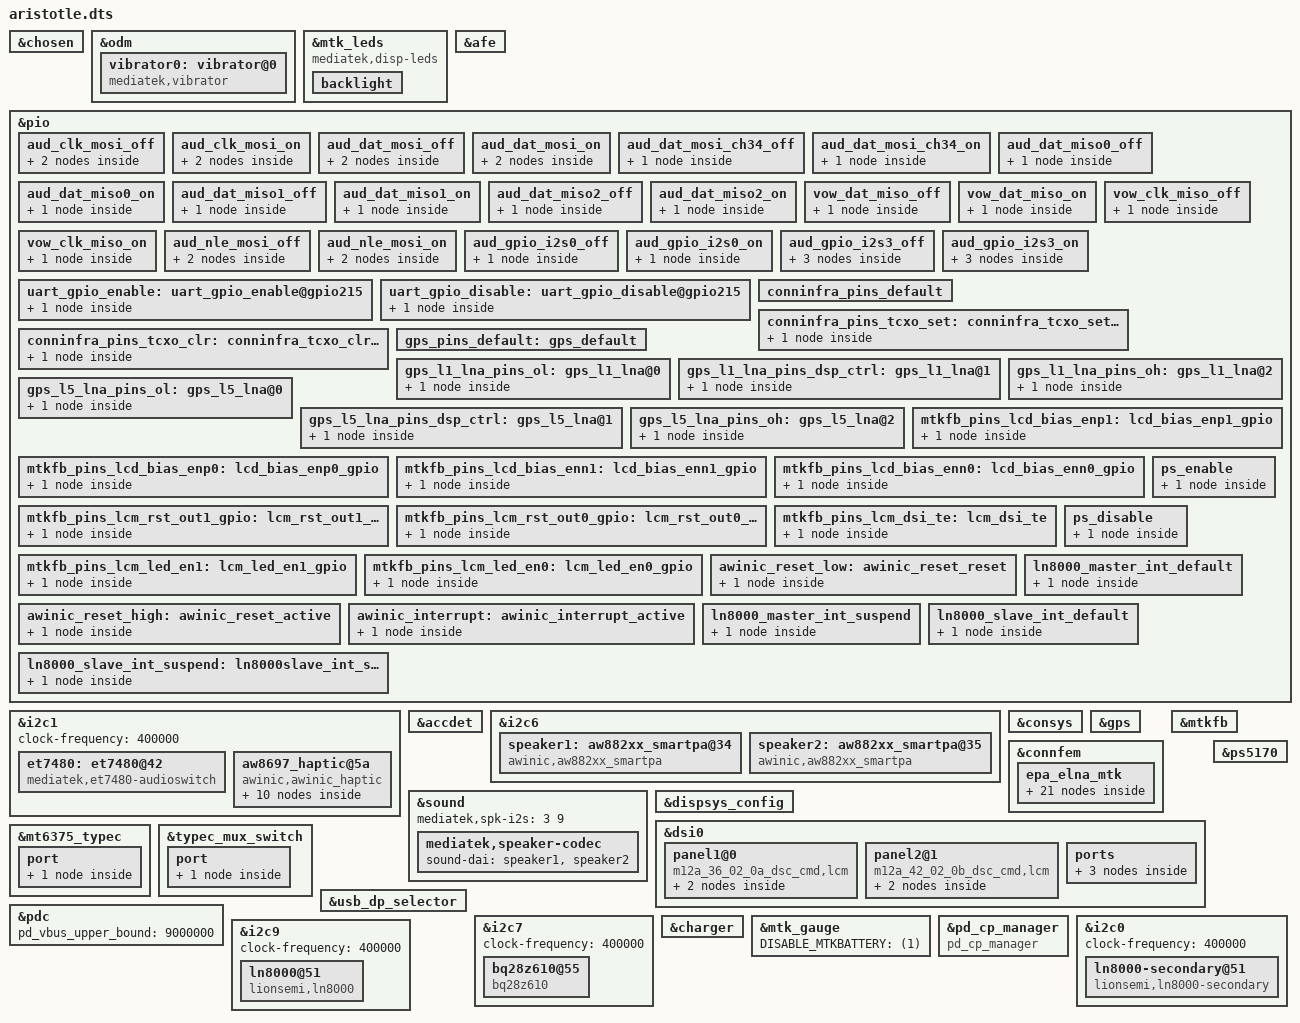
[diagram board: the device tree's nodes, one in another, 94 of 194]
// SPDX-License-Identifier: (GPL-2.0 OR MIT)
/*
 * Copyright (C) 2020 MediaTek Inc.
 * Author: Chun-Hung Wu <chun-hung.wu@mediatek.com>
 */
/dts-v1/;
/plugin/;
#include <dt-bindings/interrupt-controller/arm-gic.h>
#include <dt-bindings/interrupt-controller/irq.h>
#include <dt-bindings/phy/phy.h>
#include <dt-bindings/pinctrl/mt6895-pinfunc.h>
#include "mediatek/aristotle-mt6895-common.dtsi"

&chosen {
	bootargs_ext = "console=tty0 root=/dev/ram \
androidboot.hardware=mt6895";
};

&odm {
	vibrator0:vibrator@0 {
		compatible = "mediatek,vibrator";
		vib_timer = <25>;
		vib_limit = <9>;
		vib_vol= <9>;
	};
};

&mtk_leds {
	compatible = "mediatek,disp-leds";

	backlight {
		max-brightness = <16383>;
		min-brightness = <1>;
		max-hw-brightness = <16383>;
		led-mode = <4>;
		default-state = "FifteenPercent";
	};
};

/* AUDIO GPIO standardization start */
&afe {
	pinctrl-names = "aud_clk_mosi_off",
			"aud_clk_mosi_on",
			"aud_dat_mosi_off",
			"aud_dat_mosi_on",
			"aud_dat_mosi_ch34_off",
			"aud_dat_mosi_ch34_on",
			"aud_dat_miso0_off",
			"aud_dat_miso0_on",
			"aud_dat_miso1_off",
			"aud_dat_miso1_on",
			"aud_dat_miso2_off",
			"aud_dat_miso2_on",
			"vow_dat_miso_off",
			"vow_dat_miso_on",
			"vow_clk_miso_off",
			"vow_clk_miso_on",
			"aud_gpio_i2s3_off",
			"aud_gpio_i2s3_on",
			"aud_gpio_i2s0_off",
			"aud_gpio_i2s0_on";
	pinctrl-0 = <&aud_clk_mosi_off>;
	pinctrl-1 = <&aud_clk_mosi_on>;
	pinctrl-2 = <&aud_dat_mosi_off>;
	pinctrl-3 = <&aud_dat_mosi_on>;
	pinctrl-4 = <&aud_dat_mosi_ch34_off>;
	pinctrl-5 = <&aud_dat_mosi_ch34_on>;
	pinctrl-6 = <&aud_dat_miso0_off>;
	pinctrl-7 = <&aud_dat_miso0_on>;
	pinctrl-8 = <&aud_dat_miso1_off>;
	pinctrl-9 = <&aud_dat_miso1_on>;
	pinctrl-10 = <&aud_dat_miso2_off>;
	pinctrl-11 = <&aud_dat_miso2_on>;
	pinctrl-12 = <&vow_dat_miso_off>;
	pinctrl-13 = <&vow_dat_miso_on>;
	pinctrl-14 = <&vow_clk_miso_off>;
	pinctrl-15 = <&vow_clk_miso_on>;
	pinctrl-16 = <&aud_gpio_i2s3_off>;
	pinctrl-17 = <&aud_gpio_i2s3_on>;
	pinctrl-18 = <&aud_gpio_i2s0_off>;
	pinctrl-19 = <&aud_gpio_i2s0_on>;
};
&pio {
	aud_clk_mosi_off: aud_clk_mosi_off {
		pins_cmd1_dat {
			pinmux = <PINMUX_GPIO202__FUNC_GPIO202>;
			input-enable;
			bias-pull-down;
		};
		pins_cmd2_dat {
			pinmux = <PINMUX_GPIO203__FUNC_GPIO203>;
			input-enable;
			bias-pull-down;
		};
	};
	aud_clk_mosi_on: aud_clk_mosi_on {
		pins_cmd1_dat {
			pinmux = <PINMUX_GPIO202__FUNC_AUD_CLK_MOSI>;
			input-schmitt-enable;
			bias-disable;
		};
		pins_cmd2_dat {
			pinmux = <PINMUX_GPIO203__FUNC_AUD_SYNC_MOSI>;
			input-schmitt-enable;
			bias-disable;
		};
	};
	aud_dat_mosi_off: aud_dat_mosi_off {
		pins_cmd1_dat {
			pinmux = <PINMUX_GPIO204__FUNC_GPIO204>;
			input-enable;
			bias-pull-down;
		};
		pins_cmd2_dat {
			pinmux = <PINMUX_GPIO205__FUNC_GPIO205>;
			input-enable;
			bias-pull-down;
		};
	};
	aud_dat_mosi_on: aud_dat_mosi_on {
		pins_cmd1_dat {
			pinmux = <PINMUX_GPIO204__FUNC_AUD_DAT_MOSI0>;
			input-schmitt-enable;
			bias-disable;
		};
		pins_cmd2_dat {
			pinmux = <PINMUX_GPIO205__FUNC_AUD_DAT_MOSI1>;
			input-schmitt-enable;
			bias-disable;
		};
	};
	aud_dat_mosi_ch34_off: aud_dat_mosi_ch34_off {
		pins_cmd1_dat {
			pinmux = <PINMUX_GPIO206__FUNC_GPIO206>;
			input-enable;
			bias-pull-down;
		};
	};
	aud_dat_mosi_ch34_on: aud_dat_mosi_ch34_on {
		pins_cmd1_dat {
			pinmux = <PINMUX_GPIO206__FUNC_AUD_DAT_MOSI2>;
			input-schmitt-enable;
			bias-disable;
		};
	};
	aud_dat_miso0_off: aud_dat_miso0_off {
		pins_cmd1_dat {
			pinmux = <PINMUX_GPIO209__FUNC_GPIO209>;
			input-enable;
			bias-pull-down;
		};
	};
	aud_dat_miso0_on: aud_dat_miso0_on {
		pins_cmd1_dat {
			pinmux = <PINMUX_GPIO209__FUNC_AUD_DAT_MISO0>;
			input-schmitt-enable;
			bias-disable;
		};
	};
	aud_dat_miso1_off: aud_dat_miso1_off {
		pins_cmd1_dat {
			pinmux = <PINMUX_GPIO210__FUNC_GPIO210>;
			input-enable;
			bias-disable;
		};
	};
	aud_dat_miso1_on: aud_dat_miso1_on {
		pins_cmd1_dat {
			pinmux = <PINMUX_GPIO210__FUNC_AUD_DAT_MISO1>;
			input-schmitt-enable;
			bias-disable;
		};
	};
	aud_dat_miso2_off: aud_dat_miso2_off {
		pins_cmd1_dat {
			pinmux = <PINMUX_GPIO211__FUNC_GPIO211>;
			input-enable;
			bias-pull-down;
		};
	};
	aud_dat_miso2_on: aud_dat_miso2_on {
		pins_cmd1_dat {
			pinmux = <PINMUX_GPIO211__FUNC_AUD_DAT_MISO2>;
			input-schmitt-enable;
			bias-disable;
		};
	};
	vow_dat_miso_off: vow_dat_miso_off {
		pins_cmd1_dat {
			pinmux = <PINMUX_GPIO209__FUNC_GPIO209>;
			input-enable;
			bias-pull-down;
		};
	};
	vow_dat_miso_on: vow_dat_miso_on {
		pins_cmd1_dat {
			pinmux = <PINMUX_GPIO209__FUNC_VOW_DAT_MISO>;
			input-schmitt-enable;
			bias-disable;
		};
	};
	vow_clk_miso_off: vow_clk_miso_off {
		pins_cmd1_dat {
			pinmux = <PINMUX_GPIO210__FUNC_GPIO210>;
			input-enable;
			bias-pull-down;
		};
	};
	vow_clk_miso_on: vow_clk_miso_on {
		pins_cmd1_dat {
			pinmux = <PINMUX_GPIO210__FUNC_VOW_CLK_MISO>;
			input-schmitt-enable;
			bias-disable;
		};
	};
	aud_nle_mosi_off: aud_nle_mosi_off {
		pins_cmd1_dat {
			pinmux = <PINMUX_GPIO207__FUNC_GPIO207>;
			input-enable;
			bias-pull-down;
		};
		pins_cmd2_dat {
			pinmux = <PINMUX_GPIO208__FUNC_GPIO208>;
			input-enable;
			bias-pull-down;
		};
	};
	aud_nle_mosi_on: aud_nle_mosi_on {
		pins_cmd1_dat {
			pinmux = <PINMUX_GPIO207__FUNC_AUD_NLE_MOSI1>;
			input-schmitt-enable;
			bias-disable;
		};
		pins_cmd2_dat {
			pinmux = <PINMUX_GPIO208__FUNC_AUD_NLE_MOSI0>;
			input-schmitt-enable;
			bias-disable;
		};
	};
	aud_gpio_i2s0_off: aud_gpio_i2s0_off {
		pins_cmd1_dat {
			pinmux = <PINMUX_GPIO23__FUNC_GPIO23>;
			input-enable;
			bias-pull-down;
		};
	};
	aud_gpio_i2s0_on: aud_gpio_i2s0_on {
		pins_cmd1_dat {
			pinmux = <PINMUX_GPIO23__FUNC_I2S0_DI>;
			input-schmitt-enable;
			bias-disable;
		};
	};
	aud_gpio_i2s3_off: aud_gpio_i2s3_off {
		pins_cmd1_dat {
			pinmux = <PINMUX_GPIO21__FUNC_GPIO21>;
			input-enable;
			bias-pull-down;
		};
		pins_cmd2_dat {
			pinmux = <PINMUX_GPIO22__FUNC_GPIO22>;
			input-enable;
			bias-pull-down;
		};
		pins_cmd3_dat {
			pinmux = <PINMUX_GPIO24__FUNC_GPIO24>;
			input-enable;
			bias-pull-down;
		};
	};
	aud_gpio_i2s3_on: aud_gpio_i2s3_on {
		pins_cmd1_dat {
			pinmux = <PINMUX_GPIO21__FUNC_I2S3_BCK>;
			input-schmitt-enable;
			bias-disable;
		};
		pins_cmd2_dat {
			pinmux = <PINMUX_GPIO22__FUNC_I2S3_LRCK>;
			input-schmitt-enable;
			bias-disable;
		};
		pins_cmd3_dat {
			pinmux = <PINMUX_GPIO24__FUNC_I2S3_DO>;
			input-schmitt-enable;
			bias-disable;
		};
	};
};
/* AUDIO GPIO standardization end */

/* Audio Switch start */
&pio {
        uart_gpio_enable: uart_gpio_enable@gpio215 {
                pins_cmd_dat {
                        pinmux = <PINMUX_GPIO215__FUNC_GPIO215>;
                        slew-rate = <1>;
                        bias-disable;
                        output-low;
                };
        };
        uart_gpio_disable: uart_gpio_disable@gpio215 {
                pins_cmd_dat {
                        pinmux = <PINMUX_GPIO215__FUNC_GPIO215>;
                        slew-rate = <1>;
                        bias-disable;
                        output-high;
                };
        };
};
&i2c1 {
        et7480: et7480@42 {
                status = "ok";
                compatible = "mediatek,et7480-audioswitch";
                reg = <0x42>;
                pinctrl-names = "uart_enable", "uart_disable";
                pinctrl-0 = <&uart_gpio_enable>;
                pinctrl-1 = <&uart_gpio_disable>;
        };
};
&accdet {
        /* accdet micbias voltage: 0x09:2.85v 0x08:2.8v 0x07,
         * 2.7v;0x05,2.5v;0x02,1.9v
         */
        accdet-mic-vol = <5>;
        /*1:ACC mode, 2:low cost without in bias, 6:low cost with in bias*/
        accdet-mic-mode = <2>;
        et7480-i2c-handle = <&et7480>;
};
/* Audio Swtich end */

&i2c6 {
	speaker1: aw882xx_smartpa@34 {
		compatible = "awinic,aw882xx_smartpa";
		#sound-dai-cells = <0>;
		reg = <0x34>;
		reset-gpio = <&pio 213 0>;
		irq-gpio = <&pio 15 0x0>;
		spk-sw-gpio = <&pio 160 0x0>;
		sound-channel = <0>;
		aw-re-min = <4000>;
		aw-re-max= <30000>;
		/*aw-cali-mode = "none";*/
		status = "okay";
	};

        speaker2: aw882xx_smartpa@35 {
		compatible = "awinic,aw882xx_smartpa";
		#sound-dai-cells = <0>;
		reg = <0x35>;
		reset-gpio = <&pio 213 0>;
		irq-gpio = <&pio 19 0x0>;
		sound-channel = <1>;
		aw-re-min = <4000>;
		aw-re-max= <30000>;
		/*aw-cali-mode = "none";*/
		status = "okay";
        };
};

/* CONNSYS TCXO GPIO start */
&consys {
	tcxo_support = "false";
	pinctrl-names = "default", "conninfra_tcxo_set", "conninfra_tcxo_clr";
	pinctrl-0 = <&conninfra_pins_default>;
	pinctrl-1 = <&conninfra_pins_tcxo_set>;
	pinctrl-2 = <&conninfra_pins_tcxo_clr>;
	status = "okay";
};

&pio {
	conninfra_pins_default: conninfra_pins_default {
	};
	conninfra_pins_tcxo_set: conninfra_tcxo_set@gpio {
		pins_cmd_dat {
			pinmux = <PINMUX_GPIO108__FUNC_CONN_TCXOENA_REQ>;
		};
	};
	conninfra_pins_tcxo_clr: conninfra_tcxo_clr@gpio {
		pins_cmd_dat {
			pinmux = <PINMUX_GPIO108__FUNC_GPIO108>;
		};
	};
};
/* CONNSYS TCXO GPIO end */

/* GPS GPIO standardization start */
&pio {
	gps_pins_default: gps_default {
	};

	gps_l1_lna_pins_ol: gps_l1_lna@0 {
		pins_cmd_dat {
			pinmux = <PINMUX_GPIO16__FUNC_GPIO16>;
			output-low;
		};
	};
	gps_l1_lna_pins_dsp_ctrl: gps_l1_lna@1 {
		pins_cmd_dat {
			pinmux = <PINMUX_GPIO16__FUNC_GPS_L1_ELNA_EN>;
		};
	};
	gps_l1_lna_pins_oh: gps_l1_lna@2 {
		pins_cmd_dat {
			pinmux = <PINMUX_GPIO16__FUNC_GPIO16>;
			output-high;
		};
	};

	gps_l5_lna_pins_ol: gps_l5_lna@0 {
		pins_cmd_dat {
			pinmux = <PINMUX_GPIO17__FUNC_GPIO17>;
			output-low;
		};
	};
	gps_l5_lna_pins_dsp_ctrl: gps_l5_lna@1 {
		pins_cmd_dat {
			pinmux = <PINMUX_GPIO17__FUNC_GPS_L5_ELNA_EN>;
		};
	};
	gps_l5_lna_pins_oh: gps_l5_lna@2 {
		pins_cmd_dat {
			pinmux = <PINMUX_GPIO17__FUNC_GPIO17>;
			output-high;
		};
	};
};

&gps {
	pinctrl-names = "default",
		"gps_l1_lna_disable",
		"gps_l1_lna_dsp_ctrl",
		"gps_l1_lna_enable",
		"gps_l5_lna_disable",
		"gps_l5_lna_dsp_ctrl",
		"gps_l5_lna_enable";
	pinctrl-0 = <&gps_pins_default>;
	pinctrl-1 = <&gps_l1_lna_pins_ol>;
	pinctrl-2 = <&gps_l1_lna_pins_dsp_ctrl>;
	pinctrl-3 = <&gps_l1_lna_pins_oh>;
	pinctrl-4 = <&gps_l5_lna_pins_ol>;
	pinctrl-5 = <&gps_l5_lna_pins_dsp_ctrl>;
	pinctrl-6 = <&gps_l5_lna_pins_oh>;
	status = "okay";
};
/* GPS GPIO standardization end */

/* ConnFem start */
&connfem {
#if 0 /* Enable epa_elna node to support Wifi & BT ePA/eLNA FEM on customer load */
	epa_elna {
		parts = <&wlan7207h &wlan7207c>;

		wifi {
			flags-0 {
				open-loop;
			};
		};

		bt {
			flags-0 {
				/* choose one of: epa_elna / epa / elna / bypass */
				epa_elna;
			};
		};
	};
#endif

	epa_elna_mtk {
		parts = <&nofem &nofem>,		/* [0]iPA/iLNA */
			<&wlan7207h &wlan7207c>,	/* [1]7207C: Wifi Open, BT bypass */
			<&wlan7207h &wlan7207c>,	/* [2]7207C: Wifi Open, BT ePA/eLNA */
			<&wlan7207h &wlan7207c>,	/* [3]7207C: Wifi Closed, BT bypass */
			<&wlan7207h &wlan7207c>,	/* [4]7207C: Wifi Closed, BT ePA/eLNA */
			<&wlan7207h &wlan7205c>,	/* [5]7205C: Wifi Open, BT bypass */
			<&wlan7207h &wlan7205c>,	/* [6]7205C: Wifi Open, BT ePA/eLNA */
			<&wlan7207h &wlan7205c>,	/* [7]7205C: Wifi Closed, BT bypass */
			<&wlan7207h &wlan7205c>,	/* [8]7205C: Wifi Closed, BT ePA/eLNA */
			<&qm42195 &qm45197>,		/* [9]QM: Wifi Open, BT bypass */
			<&qm42195 &qm45197>,		/* [10]QM: Wifi Open, BT ePA/eLNA */
			<&qm42195 &qm45197>,		/* [11]QM: Wifi Closed, BT bypass */
			<&qm42195 &qm45197>,		/* [12]QM: Wifi Closed, BT ePA/eLNA */
			<&qm42195 &nofem>;		/* [13]QM/A bnad no FEM: Wifi Closed, BT ePA/eLNA */

		wifi {
			flags-1 {
				open-loop;
			};
			flags-2 {
				open-loop;
			};
			flags-5 {
				open-loop;
			};
			flags-6 {
				open-loop;
			};
			flags-9 {
				open-loop;
			};
			flags-10 {
				open-loop;
			};
		};

		bt {
			/* choose one of: epa_elna / epa / elna / bypass */
			flags-1 {
				bypass;
			};
			flags-2 {
				epa_elna;
			};
			flags-3 {
				bypass;
			};
			flags-4 {
				epa_elna;
			};
			flags-5 {
				bypass;
			};
			flags-6 {
				epa_elna;
			};
			flags-7 {
				bypass;
			};
			flags-8 {
				epa_elna;
			};
			flags-9 {
				bypass;
			};
			flags-10 {
				epa_elna;
			};
			flags-11 {
				bypass;
			};
			flags-12 {
				epa_elna;
			};
			flags-13 {
				epa_elna;
			};
		};
	};
};
/* ConnFem end */

&sound {
	mediatek,spk-i2s = <3 9>;
	mediatek,speaker-codec {
		sound-dai = <&speaker1>, <&speaker2>;
	};
};

&pio {
	mtkfb_pins_lcd_bias_enp1: lcd_bias_enp1_gpio {
		pins_cmd_dat {
			pinmux = <PINMUX_GPIO39__FUNC_GPIO39>;
			slew-rate = <1>;
			output-high;
		};
	};

	mtkfb_pins_lcd_bias_enp0: lcd_bias_enp0_gpio {
		pins_cmd_dat {
			pinmux = <PINMUX_GPIO39__FUNC_GPIO39>;
			slew-rate = <1>;
			output-low;
		};
	};

	mtkfb_pins_lcd_bias_enn1: lcd_bias_enn1_gpio {
		pins_cmd_dat {
			pinmux = <PINMUX_GPIO39__FUNC_GPIO39>;
			slew-rate = <1>;
			output-high;
		};
	};

	mtkfb_pins_lcd_bias_enn0: lcd_bias_enn0_gpio {
		pins_cmd_dat {
			pinmux = <PINMUX_GPIO39__FUNC_GPIO39>;
			slew-rate = <1>;
			output-low;
		};
	};

	mtkfb_pins_lcm_rst_out1_gpio: lcm_rst_out1_gpio {
		pins_cmd_dat {
			pinmux = <PINMUX_GPIO41__FUNC_GPIO41>;
			slew-rate = <1>;
			output-high;
		};
	};

	mtkfb_pins_lcm_rst_out0_gpio: lcm_rst_out0_gpio {
		pins_cmd_dat {
			pinmux = <PINMUX_GPIO41__FUNC_GPIO41>;
			slew-rate = <1>;
			output-low;
		};
	};
	mtkfb_pins_lcm_dsi_te: lcm_dsi_te {
		pins_cmd_dat {
			pinmux = <PINMUX_GPIO40__FUNC_DSI_TE>;
		};
	};

	mtkfb_pins_lcm_led_en1: lcm_led_en1_gpio {
		pins_cmd_dat {
			pinmux = <PINMUX_GPIO51__FUNC_GPIO51>;
			slew-rate = <1>;
			output-high;
		};
	};

	mtkfb_pins_lcm_led_en0: lcm_led_en0_gpio {
		pins_cmd_dat {
			pinmux = <PINMUX_GPIO51__FUNC_GPIO51>;
			slew-rate = <1>;
			output-low;
		};
	};
};

&mtkfb {
	pinctrl-names = "lcd_bias_enp1_gpio", "lcd_bias_enp0_gpio",
		"lcd_bias_enn1_gpio", "lcd_bias_enn0_gpio",
		"lcm_rst_out1_gpio", "lcm_rst_out0_gpio",
		"mode_te_te", "lcm_led_en1_gpio", "lcm_led_en0_gpio";
	pinctrl-0 = <&mtkfb_pins_lcd_bias_enp1>;
	pinctrl-1 = <&mtkfb_pins_lcd_bias_enp0>;
	pinctrl-2 = <&mtkfb_pins_lcd_bias_enn1>;
	pinctrl-3 = <&mtkfb_pins_lcd_bias_enn0>;
	pinctrl-4 = <&mtkfb_pins_lcm_rst_out1_gpio>;
	pinctrl-5 = <&mtkfb_pins_lcm_rst_out0_gpio>;
	pinctrl-6 = <&mtkfb_pins_lcm_dsi_te>;
	pinctrl-7 = <&mtkfb_pins_lcm_led_en1>;
	pinctrl-8 = <&mtkfb_pins_lcm_led_en0>;

	status = "okay";
};
&dispsys_config {
	pinctrl-names =
		"lcm_rst_out1_gpio", "lcm_rst_out0_gpio",
		"mode_te_te";
	pinctrl-0 = <&mtkfb_pins_lcm_rst_out1_gpio>;
	pinctrl-1 = <&mtkfb_pins_lcm_rst_out0_gpio>;
	pinctrl-2 = <&mtkfb_pins_lcm_dsi_te>;
	status = "okay";
};

&dsi0 {
	status = "okay";
	#address-cells = <1>;
	#size-cells = <0>;
	panel1@0 {
		compatible = "m12a_36_02_0a_dsc_cmd,lcm";
		reg = <0>;
		mi,esd-err-irq-gpio = <&pio 1 0x2002>;
		reset-gpios = <&pio 41 0>;
		dvdd-gpios = <&pio 147 0>;
		cam-gpios = <&pio 158 0>;
		vibr-supply = <&mt6368_vibr>;
		vrf18-supply = <&mt6368_vrf18_aif>;
		pinctrl-names = "default";
		port {
			panel_in1: endpoint {
				remote-endpoint = <&dsi_out1>;
			};
		};
	};

	panel2@1 {
		compatible = "m12a_42_02_0b_dsc_cmd,lcm";
		reg = <1>;
		mi,esd-err-irq-gpio = <&pio 1 0x2002>;
		reset-gpios = <&pio 41 0>;
		dvdd-gpios = <&pio 147 0>;
		cam-gpios = <&pio 158 0>;
		vibr-supply = <&mt6368_vibr>;
		vrf18-supply = <&mt6368_vrf18_aif>;
		pinctrl-names = "default";
		port {
			panel_in2: endpoint {
				remote-endpoint = <&dsi_out2>;
			};
		};
	};
	ports {
		port {
			dsi_out1: endpoint@0 {
				remote-endpoint = <&panel_in1>;
			};
			/* dsi_out2 but dsi_out1 fixes warning. It only allows pairing endpoints.*/
			dsi_out2: endpoint@1 {
				remote-endpoint = <&panel_in2>;
			};
		};
	};
};

/* usb typec mux start */
&pio {

	ps_enable: ps_enable {
		pins_cmd_dat {
			pinmux = <PINMUX_GPIO158__FUNC_GPIO158>;
			output-high;
		};
	};

	ps_disable: ps_disable {
		pins_cmd_dat {
			pinmux = <PINMUX_GPIO158__FUNC_GPIO158>;
			output-low;
		};
	};

};

&mt6375_typec {
	port {
		tcpc_typec_usb: endpoint@0 {
			remote-endpoint = <&ssusb_mux>;
		};
	};
};

&typec_mux_switch {
	orientation-switch;
	mode-switch;
	accessory;
	port {
		ssusb_mux: endpoint@0 {
			remote-endpoint = <&tcpc_typec_usb>;
		};
	};
};

&ps5170 {
	pinctrl-names = "enable", "disable";
	pinctrl-0 = <&ps_enable>;
	pinctrl-1 = <&ps_disable>;
	status = "okay";
};

&usb_dp_selector {
	status = "okay";
};
/* usb typec mux end */

&pdc {
	pd_vbus_upper_bound = <9000000>;
};

/* Awinic Haptic start */
&pio {
	awinic_reset_low: awinic_reset_reset {
		pins_cmd_dat {
			pinmux = <PINMUX_GPIO117__FUNC_GPIO117>;
			drive-strength = <2>;
			bias-disable;
			output-low;
		};
	};
	awinic_reset_high: awinic_reset_active {
		pins_cmd_dat {
			pinmux = <PINMUX_GPIO117__FUNC_GPIO117>;
			drive-strength = <2>;
			bias-disable;
			output-high;
		};
	};
	awinic_interrupt: awinic_interrupt_active {
		pins_cmd_dat {
			pinmux = <PINMUX_GPIO127__FUNC_GPIO127>;
			drive-strength = <2>;
			bias-pull-up;
			input-enable;
		};
	};
};

&i2c1 {
    clock-frequency = <400000>;
	status = "ok";
        aw8697_haptic@5a {
		compatible = "awinic,awinic_haptic";
		reg = <0x5A>;
		reset-gpio = <&pio 117 0>;
		irq-gpio = <&pio 127 0>;
		pinctrl-names = "awinic_reset_reset","awinic_reset_active","awinic_interrupt_active";
		pinctrl-0 = <&awinic_reset_low>;
		pinctrl-1 = <&awinic_reset_high>;
		pinctrl-2 = <&awinic_interrupt>;
		/*----------------------aw8692x----------------------*/
		aw86927_vib_mode = < 0 >; /* mode: RAM mode->0; CONT mode->1 */
		aw86927_vib_f0_pre = < 1700 >;
		aw86927_comp_gain_temp = < 182 >;
		aw86927_vib_f0_cali_percen = < 7 >;
		aw86927_vib_cont_drv1_lvl = < 0x7F >;
		aw86927_vib_cont_drv2_lvl = < 0x36 >;
		aw86927_vib_cont_drv1_time = < 0x04 >;
		aw86927_vib_cont_drv2_time = < 0x06 >;
		aw86927_vib_cont_drv_width = < 0x6A >;
		aw86927_vib_cont_wait_num = < 0x06 >;
		aw86927_vib_cont_brk_time = < 0x08 >;
		aw86927_vib_cont_track_margin = < 0x0C >;
		aw86927_vib_brk_bst_md = < 0 >;
		aw86927_vib_cont_tset = < 0x06 >;
		aw86927_vib_cont_bemf_set = < 0x02 >;
		aw86927_vib_cont_bst_brk_gain = < 0x05 >;
		aw86927_vib_cont_brk_gain = < 0x08 >;
		aw86927_vib_d2s_gain = < 0x04 >;
		aw86927_vib_trig_config = < 1 0 1 1 1 2 0 0
					    1 0 0 1 0 2 0 0
					    1 0 0 1 0 2 0 0 >;
		aw86927_vib_bst_vol_default = < 0x64 >;
		aw86927_vib_bst_vol_ram = < 0x64 >;
		aw86927_vib_bst_vol_rtp = < 0x64 >;
		/*--------------------common--------------------*/
		vib_effect_id_boundary = < 10 >;
		vib_effect_max = < 197 >; /*vib_effect_max must bigger than vib_effect_id*/
		vib_rtp_time = < 20 20 20 20 20 20 20 20 20000 15000
				15000 20000 25000 15000 30000 25000 20000 20000 20000 20000
				20000 20000 20000 20000 20000 20000 20000 20000 20000 20000
				20000 20000 20000 20000 20000 20000 20000 20000 20000 20000
				20000 20000 20000 20000 20000 20000 20000 20000 20000 20000
				20000 20000 20000 20000 20000 20000 20000 20000 20000 20000
				20000 20000 20000 20000 20000 20000 20000 20000 20000 20000
				20000 20000 20000 20000 20000 20000 20000 20000 20000 20000
				20000 20000 20000 20000 20000 20000 20000 20000 20000 20000
				20000 20000 20000 20000 20000 20000 20000 20000 20000 20000
				20000 20000 20000 20000 20000 20000 20000 20000 20000 20000
				20000 20000 20000 20000 20000 20000 20000 20000 20000 20000
				20000 20000 20000 20000 20000 20000 20000 20000 20000 20000
				20000 20000 20000 20000 20000 20000 20000 20000 20000 20000
				20000 20000 20000 20000 20000 20000 20000 20000 20000 20000
				20000 20000 20000 20000 20000 20000 20000 20000 20000 20000
				20000 20000 20000 20000 20000 20000 20000 20000 20000 20000
				20000 20000 20000 20000 20000 >;
		status = "ok";
		wf_0 {
			/*CLICK*/
			mtk,effect-id = <0>;
			mtk,wf-vmax-mv = <3600>;
			mtk,wf-pattern = [3e 3e];
			mtk,wf-brake-pattern = [02 01 00 00];
			mtk,wf-play-rate-us = <20000>;
		};
		wf_1 {
			/*DOUBLE CLICK*/
			mtk,effect-id = <1>;
			mtk,wf-vmax-mv = <3600>;
			mtk,wf-pattern = [7e 3e];
			mtk,wf-brake-pattern = [03 01 00 00];
			mtk,wf-play-rate-us = <20000>;
		};
		wf_2 {
			/*TICK*/
			mtk,effect-id = <2>;
			mtk,wf-vmax-mv = <3600>;
			mtk,wf-pattern = [7e 3e];
			mtk,wf-brake-pattern = [02 01 00 00];
			mtk,wf-play-rate-us = <20000>;
		};
		wf_3 {
			/*THUD*/
			mtk,effect-id = <3>;
			mtk,wf-vmax-mv = <3600>;
			mtk,wf-pattern = [3e 3e];
			mtk,wf-brake-pattern = [02 01 00 00];
			mtk,wf-play-rate-us = <20000>;
		};
		wf_4 {
			/*POP*/
			mtk,effect-id = <4>;
			mtk,wf-vmax-mv = <3600>;
			mtk,wf-pattern = [3e 3e];
			mtk,wf-brake-pattern = [02 01 00 00];
			mtk,wf-play-rate-us = <28000>;
		};
		wf_5 {
			/*HEAVY CLICK*/
			mtk,effect-id = <5>;
			mtk,wf-vmax-mv = <3600>;
			mtk,wf-pattern = [7e 7e 7e];
			mtk,wf-brake-pattern = [03 03 01 00];
			mtk,wf-play-rate-us = <20000>;
		};
		wf_6 {
			/*id 6*/
			mtk,effect-id = <6>;
			mtk,wf-vmax-mv = <3600>;
			mtk,wf-pattern = [3e 3e];
			mtk,wf-brake-pattern = [02 01 00 00];
			mtk,wf-play-rate-us = <20000>;
		};
		wf_7 {
			/*id 7*/
			mtk,effect-id = <7>;
			mtk,wf-vmax-mv = <3600>;
			mtk,wf-pattern = [3e 3e];
			mtk,wf-brake-pattern = [02 01 00 00];
			mtk,wf-play-rate-us = <20000>;
		};
		wf_8 {
			/*id 8*/
			mtk,effect-id = <8>;
			mtk,wf-vmax-mv = <3600>;
			mtk,wf-pattern = [3e 3e];
			mtk,wf-brake-pattern = [02 01 00 00];
			mtk,wf-play-rate-us = <20000>;
		};
		wf_9 {
			/*id 9*/
			mtk,effect-id = <9>;
			mtk,wf-vmax-mv = <3600>;
			mtk,wf-pattern = [3e 3e];
			mtk,wf-brake-pattern = [02 01 00 00];
			mtk,wf-play-rate-us = <20000>;
		};
	};
	/* Awinic Haptic end */
};

/* Charger Start */
&i2c7 {
 	clock-frequency = <400000>;
 	status = "okay";
 	bq28z610@55 {
 		compatible = "bq28z610";
 		reg = <0x55>;
 		enable_shutdown_delay;
 		normal_shutdown_vbat_1s = <3400>;
 		critical_shutdown_vbat_1s = <3340>;
 		report_full_rsoc_1s = <9700>;
 		soc_gap_1s = <2>;
 		soc_decimal_rate = <
 			0  38
 			10 35
 			20 33
 			30 33
 			40 33
 			50 33
 			60 33
 			70 30
 			80 25
 			90 20
 			95 10 >;
 	};
};

&charger {
		max_charger_voltage = <12000000>;
		fv = <4480>;
		fv_ffc = <4530>;
		iterm = <246>;
		iterm_warm = <246>;
		iterm_ffc = <1230>;
		iterm_ffc_warm = <1328>;
		iterm_2nd = <246>;
		iterm_warm_2nd = <246>;
		iterm_ffc_2nd = <1082>;
		iterm_ffc_warm_2nd = <1230>;
		/* charging current */
		usb_charger_current = <500000>;
		ac_charger_current = <1500000>;
		ac_charger_input_current = <1500000>;
		charging_host_charger_current = <900000>;
		ffc_low_tbat = <150>;
		ffc_high_tbat = <480>;
		ffc_medium_tbat = <350>;
		ffc_high_soc = <95>;
		adapter_power = <67>;
		step_fallback_hyst = <25>;
		step_forward_hyst = <5>;
		jeita_fallback_hyst = <10>;
		jeita_forward_hyst = <10>;
		burn_control_gpio = <&pio 193 0x0>;
		en_floatgnd;
		aristotle_product;
		pd2_input_current = <1700000>;
		jeita_fcc_cfg = <(-100)	0	4150	1000	738
				1	50	4150	2360	2360
				51	100	4150	3344	3344
				101	150	4150	5804	5804
				151	470	4150	12200	12200
				471	600	4100	2360	2360>;
		jeita_fv_cfg = <(-100)	0	4480
				1	50	4480
				51	100	4480
				101	150	4480
				151	470	4530
				471	600	4100>;
		/* 1- 100cls */
		step_chg_cfg_1_cycle = <3000	4250	12200
					4251	4300	8756
					4301	4480	7280
					4481	4530	5804>;
		/* 101 - 800cls */
		step_chg_cfg_100_cycle = <3000	4200	12200
					4201	4250	8756
					4251	4480	7280
					4481	4530	5804>;
		/* > 801cls */
		step_chg_cfg_800_cycle = <3000	4200	12200
					4201	4250	8756
					4251	4460	7280
					4461	4510	5804>;
		thermal_limit_dcp = <1600 1600 1600 1600 1600 1600 1600 1600 1600 1600 1600 1600 1500 1400 1200 500>;
		thermal_limit_qc2 = <2500 2500 2500 2500 2500 2500 2500 2500 2500 2500 2500 2000 1500 1500 1000 500>;
		thermal_limit_qc3_18w = <2500 2500 2500 2500 2500 2500 2400 2300 2200 2100 1500 1000 800 700 600 500>;
		thermal_limit_qc3_27w = <2500 2500 2500 2500 2500 2500 2400 2300 2200 2100 1500 1000 800 700 600 500>;
		thermal_limit_qc35 = <2500 2500 2500 2500 2500 2500 2400 2300 2200 2100 1500 1000 800 700 600 500>;
		thermal_limit_pd = <12400 10000 10000 9000 8000 8000 7000 6600 6000 5000 5000 4000 2900 2000 1000 500>;
};

&mtk_gauge {
        DISABLE_MTKBATTERY = <(1)>;
};

&pd_cp_manager {
		compatible = "pd_cp_manager";
		fv = <4478>;
		fv_ffc = <4520>;
		max_fcc = <12400>;
		max_vbus = <12000>;
		max_ibus = <6200>;
		fcc_low_hyst = <150>;
		fcc_high_hyst = <10>;
		low_tbat = <100>;
		high_tbat = <480>;
		high_vbat = <4400>;
		high_soc = <95>;
		low_fcc = <2000>;
		cv_vbat = <4480>;
		cv_vbat_ffc = <4510>;
		cv_ibat = <2000>;
		cv_ibat_bypass = <1800>;
		vbus_low_gap_div = <400>;
		vbus_high_gap_div = <600>;
		min_pdo_vbus = <8000>;
		max_pdo_vbus = <11000>;
		switch1_1_enter = <4000>;
		switch1_1_exit = <6000>;
		pdm_ibus_gap = <0>;
};

&pio {
	// ln8000-master
	ln8000_master_int_default: ln8000_master_int_default {
 	pins_cmd_dat {
 			pinmux = <PINMUX_GPIO13__FUNC_GPIO13>;
 			slew-rate = <0>;
 			bias-pull-up = <11>;
 		};
 	};
 	ln8000_master_int_suspend: ln8000_master_int_suspend {
 		pins_cmd_dat {
 			pinmux = <PINMUX_GPIO13__FUNC_GPIO13>;
 			slew-rate = <0>;
 			bias-pull-up = <11>;
 		};
 	};
 	// ln8000-slave
 	ln8000_slave_int_default: ln8000_slave_int_default {
 		pins_cmd_dat {
 			pinmux = <PINMUX_GPIO14__FUNC_GPIO14>;
 			slew-rate = <0>;
 			bias-pull-up = <11>;
 		};
 	};
 	ln8000_slave_int_suspend: ln8000slave_int_suspend {
 		pins_cmd_dat {
 			pinmux = <PINMUX_GPIO14__FUNC_GPIO14>;
 			slew-rate = <0>;
 			bias-pull-up = <11>;
 		};
 	};
};

&i2c0 {
	clock-frequency = <400000>;
	status = "okay";
	ln8000-secondary@51 {
		compatible = "lionsemi,ln8000-secondary";
		reg = <0x51>;
		pinctrl-names = "ln8000_slave_irq";
		pinctrl-0 = <&ln8000_slave_int_default &ln8000_slave_int_suspend>;
		charger_name = "quaternary_chg";
		/* bank <bit-idx> <flags: active-low> */
		//irq-gpios = <&tlmm 55 0x2002>;
		//interrupt-parent = <&tlmm>;
		//interrupts = <55 0x2002>;
		//pinctrl-names = "default";
		//pinctrl-0 = <&ln8000_int_default &ln8000_int_suspend>;
		//ln8000_charger,irq_index = <296>;
		ln8000_irq_gpio = <&pio 14 0x0>;
		/* device configuration */
		ln8000_charger,bat-ovp-threshold = <4660>;
		ln8000_charger,bat-ovp-alarm-threshold = <4625>;
		ln8000_charger,bus-ovp-threshold = <13000>;
		ln8000_charger,bus-ovp-alarm-threshold = <11000>;
		ln8000_charger,bus-ocp-threshold = <3750>;
		ln8000_charger,bus-ocp-alarm-threshold = <3500>;
		ln8000_charger,ntc-alarm-cfg  = <226>;
		/* protection enable/disable flags
		 *   vbat-ovp-disable
		 *   vbat-reg-disable
		 *   iin-ocp-disable
		 *   iin-reg-disable
		 *   tbus-mon-disable
		 *   tbat-mon-disable
		 *   tdie-prot-disable
		 *   tdie-reg-disable
		 *   revcurr-prot-disable
		 */
		ln8000_charger,tdie-prot-disable;
		ln8000_charger,tbus-mon-disable;
		ln8000_charger,tbat-mon-disable;
		ln8000_charger,iin-ocp-disable;
		ln8000_charger,iin-reg-disable;
		ln8000_charger,tdie-reg-disable;
		ln8000_charger,vbat-reg-disable;
		ln8000_charger,reset-prevent-enable;
	};
};

&i2c9 {
	clock-frequency = <400000>;
	status = "okay";
	ln8000@51 {
		compatible = "lionsemi,ln8000";
		reg = <0x51>;
		/* bank <bit-idx> <flags: active-low> */
		//irq-gpios = <&tlmm 55 0x2002>;
		pinctrl-names = "ln8000_master_irq";
		pinctrl-0 = <&ln8000_master_int_default &ln8000_master_int_suspend>;
		charger_name = "tertiary_chg";
		//interrupt-parent = <&tlmm>;
		//interrupts = <55 0x2002>;
		//pinctrl-names = "default";
		//pinctrl-0 = <&ln8000_int_default ln8000_int_suspend>;
		//ln8000_charger,irq_index = <296>;
		ln8000_irq_gpio = <&pio 13 0x0>;
		/* device configuration */
		ln8000_charger,bat-ovp-threshold = <4660>;
		ln8000_charger,bat-ovp-alarm-threshold = <4625>;
		ln8000_charger,bus-ovp-threshold = <13000>;
		ln8000_charger,bus-ovp-alarm-threshold = <11000>;
		ln8000_charger,bus-ocp-threshold = <3750>;
		ln8000_charger,bus-ocp-alarm-threshold = <3500>;
		ln8000_charger,ntc-alarm-cfg  = <226>;
		/* protection enable/disable flags
		 *   vbat-ovp-disable
		 *   vbat-reg-disable
		 *   iin-ocp-disable
		 *   iin-reg-disable
		 *   tbus-mon-disable
		 *   tbat-mon-disable
		 *   tdie-prot-disable
		 *   tdie-reg-disable
		 *   revcurr-prot-disable
		 */
		ln8000_charger,tdie-prot-disable;
		ln8000_charger,tbus-mon-disable;
		ln8000_charger,tbat-mon-disable;
		ln8000_charger,iin-ocp-disable;
		ln8000_charger,iin-reg-disable;
		ln8000_charger,tdie-reg-disable;
		ln8000_charger,vbat-reg-disable;
		ln8000_charger,reset-prevent-enable;
	};
};
/* Charger End */

#include "mediatek/aristotle_mt6895_camera_v4l2.dtsi"
#include "aristotle/cust.dtsi"
#include "xiaomi_aristotle_mt6895_touch.dtsi"


/*End of this file, DO NOT ADD ANYTHING HERE*/
